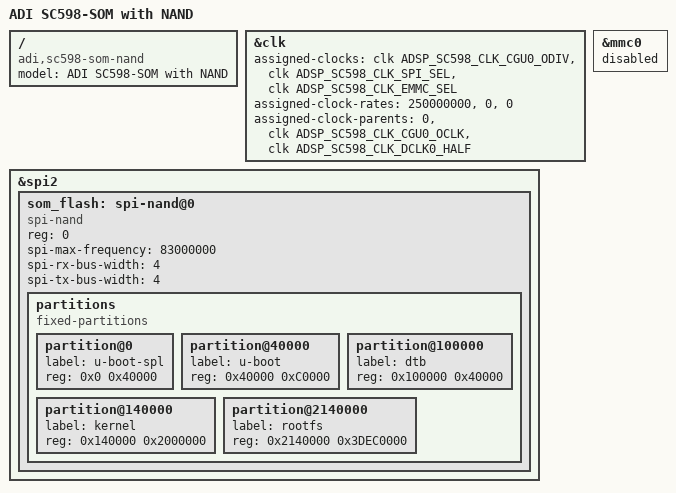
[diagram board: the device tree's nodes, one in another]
// SPDX-License-Identifier: GPL-2.0
/*
 * Copyright (c) 2026 Analog Devices Incorporated
 */

/dts-v1/;

#include "sc598-som-revE.dtsi"

/ {
  model = "ADI SC598-SOM with NAND";
  compatible = "adi,sc598-som-nand", "adi,sc59x-64";
};

/*
 * Clock configuration for faster SPI NAND performance.
 *
 * Default SPI clock sources (sclk0_0, oclk_0) are both 62.5 MHz, limiting
 * SPI speed. Reconfigure oclk_0 to 250 MHz instead of using sclk0_0
 * because sclk0_0 is shared by UARTs, I2C, timers, watchdog, and Ethernet.
 *
 *   CGU0_ODIV: 1000 MHz / 4 = 250 MHz (was / 16 = 62.5 MHz)
 *   SPI_SEL: Use oclk_0 as SPI parent
 *   EMMC_SEL: Switch eMMC to dclk_0_half (eMMC defaults to oclk_0, which
 *             would break it at 250 MHz - "Internal clock never stabilised")
 *
 * time nanddump /dev/mtd4 -l 1048576 -f /dev/null
 *   ~21 MHz (original): 0.24s (~4.4 MB/s)
 *   62.5 MHz: 0.20s (~5.2 MB/s)
 *   83.3 MHz: 0.19s (~5.5 MB/s)
 *   125 MHz: probe failed (ID reads 0xffffffff)
 */
&clk {
	assigned-clocks = <&clk ADSP_SC598_CLK_CGU0_ODIV>, <&clk ADSP_SC598_CLK_SPI_SEL>, <&clk ADSP_SC598_CLK_EMMC_SEL>;
	assigned-clock-rates = <250000000>, <0>, <0>;
	assigned-clock-parents = <0>, <&clk ADSP_SC598_CLK_CGU0_OCLK>, <&clk ADSP_SC598_CLK_DCLK0_HALF>;
};

&mmc0 {
	status = "disabled";
};

&spi2 {
	/delete-node/ is25lp01g@0;

	som_flash: spi-nand@0 {
		#address-cells = <1>;
		#size-cells = <1>;
		compatible = "spi-nand";
		reg = <0>;
		spi-max-frequency = <83000000>;
		spi-rx-bus-width = <4>;
		spi-tx-bus-width = <4>;

		partitions {
			compatible = "fixed-partitions";
			#address-cells = <1>;
			#size-cells = <1>;

			partition@0 {
				label = "u-boot-spl";
				reg = <0x0 0x40000>;
			};

			partition@40000 {
				label = "u-boot";
				reg = <0x40000 0xC0000>;
			};

			partition@100000 {
				label = "dtb";
				reg = <0x100000 0x40000>;
			};

			partition@140000 {
				label = "kernel";
				reg = <0x140000 0x2000000>;
			};

			partition@2140000 {
				label = "rootfs";
				reg = <0x2140000 0x3DEC0000>;
			};
		};
	};
};
